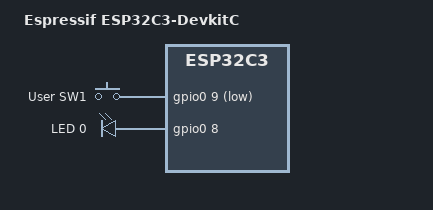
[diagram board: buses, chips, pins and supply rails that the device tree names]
/dts-v1/;

#include <espressif/esp32c3/esp32c3_wroom_n4.dtsi>
#include "esp32c3_devkitc-pinctrl.dtsi"
#include <zephyr/dt-bindings/input/input-event-codes.h>
#include <espressif/partitions_0x0_default.dtsi>

/ {
	model = "Espressif ESP32C3-DevkitC";
	compatible = "espressif,esp32c3";

	chosen {
		zephyr,sram = &sram1;
		zephyr,console = &uart0;
		zephyr,shell-uart = &uart0;
		zephyr,flash = &flash0;
		zephyr,code-partition = &slot0_partition;
		zephyr,bt-hci = &esp32_bt_hci;
	};

	aliases {
        app-led = &my_led0;
	};

	gpio_keys {
		compatible = "gpio-keys";

		user_button1: button_1 {
			label = "User SW1";
			gpios = <&gpio0 9 (GPIO_PULL_UP | GPIO_ACTIVE_LOW)>;
			zephyr,code = <INPUT_KEY_0>;
		};
	};
};

/ {

    leds {
        compatible = "gpio-leds";
        my_led0: led_0 {
            gpios = <&gpio0 8 GPIO_ACTIVE_HIGH>;
            label = "LED 0";
        };
    };
};

&gpio0 {
    status = "okay";
};

